# PIC32CK1012SG00048 register map
Vendor: Microchip Technology; Series: PIC32CKSG00; File version: 0
CPU: CM33 r0p0, little endian, MPU, FPU, DSP, 3 interrupt priority bits, 159 interrupts, 18 SAU regions
Registers are 32-bit, read-write, reset 0x0 unless marked. A register's access mark holds for its fields unless they carry their own. Offsets are from the block's base; [hi:lo] are bit positions; lines under a group give offsets from that group; {n}, {i} and the like mark numbered series; 'fields as' and 'values as' point back to an identical list.

## MCLK — Main Clock
Base 0x44012000
0x00 INTENCLR write-1-clears — Interrupt Enable Clear
  [0] CKRDY — Clock Ready Interrupt Enable
0x04 INTENSET write-1-sets — Interrupt Enable Set
  [0] CKRDY — Clock Ready Interrupt Enable
0x08 INTFLAG reset 0x1 write-1-clears — Interrupt Flag Status and Clear
  [0] CKRDY — Clock Ready
0x0C CLKDIV — Clock Divider Control
  [7:0] DIV — Clock Domain Division Factor
    1=Divide by 1; 2=Divide by 2; 4=Divide by 4; 8=Divide by 8; 16=Divide by 16; 32=Divide by 32; 64=Divide by 64; 128=Divide by 128
{0x3C+4i} CLKMSK[{i}] (i=0..8) — Peripheral Clock Enable Mask
  [31:0] MASK

## FLEXRAM — Multi-Channel RAM Controller
Base 0x44028000; register names take the prefix MCRAMC_
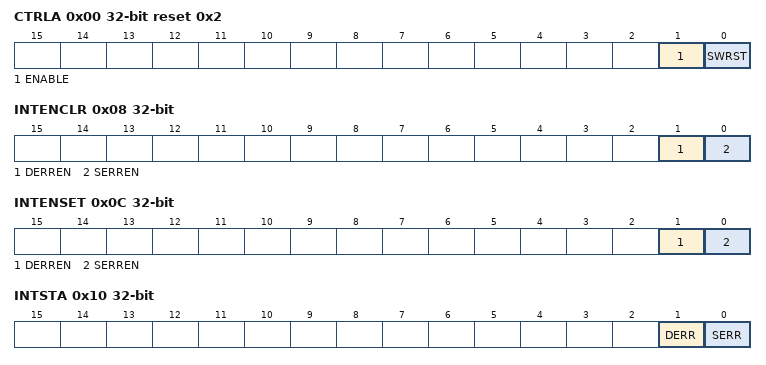
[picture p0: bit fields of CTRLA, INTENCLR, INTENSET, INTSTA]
0x00 CTRLA reset 0x2 — Control Enable A Register
  [1] ENABLE — ECC Decoder Enable
    0=ECC decoding is disabled; 1=ECC decoding is enabled
  [0] SWRST — Software Reset
    0=No effect; 1=Reset the MCRAMC. A software-triggered hardware reset of the MCRAMC user interface is performed.
0x08 INTENCLR — Interrupt Enable Clear Register
  [1] DERREN — Double Bit Error Interrupt Enable, Clear
  [0] SERREN — Single Bit Error Interrupt Enable, Clear
0x0C INTENSET — Interrupt Enable Set Register
  [1] DERREN — Double Bit Error Interrupt Enable, Set
  [0] SERREN — Single Bit Error Interrupt Enable, Set
0x10 INTSTA — Interrupt Status Register
  [1] DERR — Double Bit Error
  [0] SERR — Single Bit Error
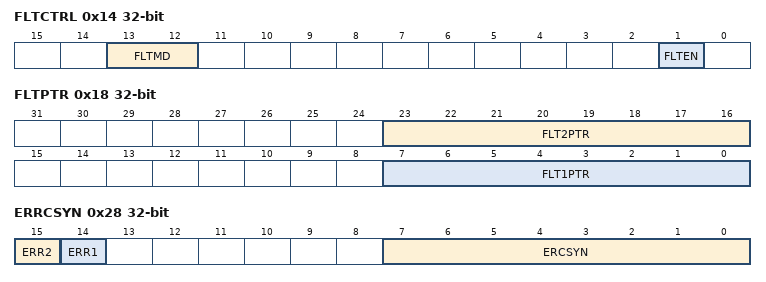
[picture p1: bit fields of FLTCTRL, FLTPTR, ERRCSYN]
0x14 FLTCTRL — Fault Injection Control Register
  [13:12] FLTMD — Fault Injection Mode
  [1] FLTEN — Fault Injection Enabled
    0=Disables fault injection; 1=Enables fault injection at FLTADR address offset as selected by FLTMD and FLTxPTR
0x18 FLTPTR — Fault Injection Pointer Register
  [23:16] FLT2PTR — Double Fault Injection Bit Pointer
  [7:0] FLT1PTR — Single Fault Injection Bit Pointer
0x1C FLTADR — Fault Injection Address Register
  [23:0] FLTADR — Fault Address Offset
0x20 ERRCADR ro — Error Capture Address Register
  [23:0] ERCADR — ECC SECDED Error Capture Address
0x24 ERRCPAR ro — Error Capture Parity Register
  [7:0] ERCPAR — ECC SECDED Error Capture Parity
0x28 ERRCSYN ro — Error Capture Syndrome Register
  [15] ERR2 — ECC Double Bit Error
    0=Not a Double bit error; 1=Double bit error
  [14] ERR1 — ECC Single Bit Error
  [7:0] ERCSYN — ECC SECDED Error Capture Syndrome
    0=Not a Single bit error; 1=Single bit error

## MPU — Memory Protection Unit
Base 0xE000ED90
Same registers: MPU_NS 0xE002ED90
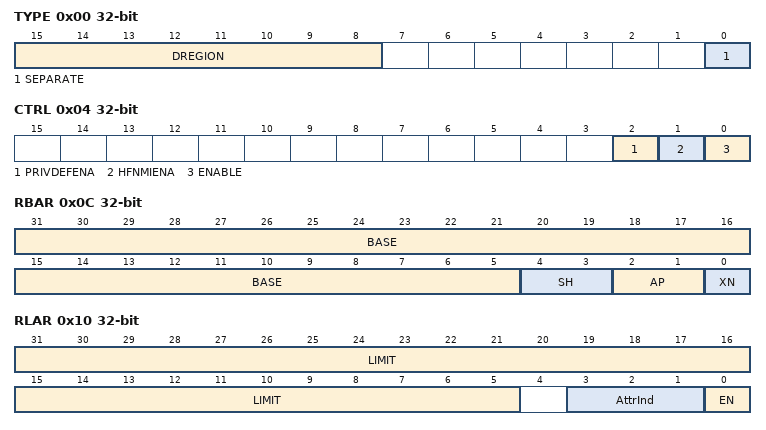
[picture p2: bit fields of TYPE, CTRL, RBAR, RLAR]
0x00 TYPE ro — MPU Type Register
  [15:8] DREGION — Number of MPU data regions
  [0] SEPARATE — Separate instructions and data address regions
0x04 CTRL — MPU Control Register
  [2] PRIVDEFENA — Privileged default enable
  [1] HFNMIENA — HardFault, NMI enable
  [0] ENABLE — MPU enable
0x08 RNR — MPU Region Number Register
  [7:0] REGION — Selected region number
0x0C RBAR — MPU Region Base Address Register
  [31:5] BASE — Base address
  [4:3] SH — Shareability
    0=NO (Non-shareable); 2=OUTER (Outer shareable); 3=INNER (Inner shareable)
  [2:1] AP — Access permissions
    0=RWPRIV (Read/write by privileged code only); 1=RWANY (Read/write by any privilege level); 2=RPRIV (Read-only by privileged code only); 3=RANY (Read-only by any privilege level)
  [0] XN — Execute Never
0x10 RLAR — MPU Region Limit Address Register
  [31:5] LIMIT — Limit address
  [3:1] AttrInd — Attribute Index
  [0] EN — Region enable
{0x14+8i} RBAR_A_RLAR_A[{i}] (i=0..3) group — MPU Region Base Address Register Alias x
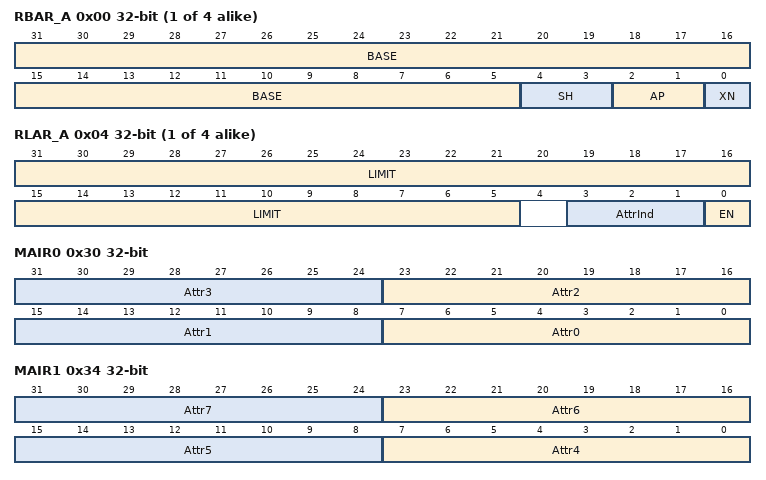
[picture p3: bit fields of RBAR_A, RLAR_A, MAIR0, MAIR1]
  0x00 RBAR_A — MPU Region Base Address Register Alias x
    fields as RBAR
  0x04 RLAR_A — MPU Region Limit Address Register Alias x
    fields as RLAR
0x30 MAIR0 — MPU Memory Attribute Indirection Register 0
  [8n+7:8n] Attr{n} (n=0..3) — Attribute of MPU region {n}
0x34 MAIR1 — MPU Memory Attribute Indirection Register 1
  [8n-25:8n-32] Attr{n} (n=4..7) — Attribute of MPU region {n}

## Notices in the file
Copyright (c) 2026 Microchip Technology Inc.
SPDX-License-Identifier: Apache-2.0
Licensed under the Apache License, Version 2.0 (the "License");
you may not use this file except in compliance with the License.
You may obtain a copy of the License at
http://www.apache.org/licenses/LICENSE-2.0
Unless required by applicable law or agreed to in writing, software
distributed under the License is distributed on an "AS IS" BASIS,
WITHOUT WARRANTIES OR CONDITIONS OF ANY KIND, either express or implied.
See the License for the specific language governing permissions and
limitations under the License.
